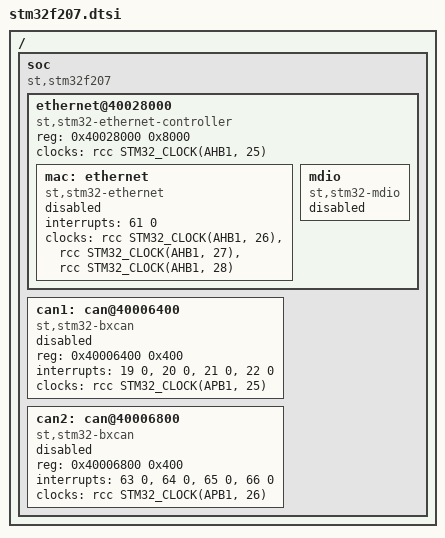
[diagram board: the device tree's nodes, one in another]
/*
 * Copyright (c) 2018 qianfan Zhao
 *
 * SPDX-License-Identifier: Apache-2.0
 */

#include <st/f2/stm32f2.dtsi>

/ {
	soc {
		compatible = "st,stm32f207", "st,stm32f2", "simple-bus";

		ethernet@40028000 {
			reg = <0x40028000 0x8000>;
			compatible = "st,stm32-ethernet-controller";
			clock-names = "stm-eth";
			clocks = <&rcc STM32_CLOCK(AHB1, 25)>;

			mac: ethernet {
				compatible = "st,stm32-ethernet";
				interrupts = <61 0>;
				clock-names = "mac-clk-tx", "mac-clk-rx",
					      "mac-clk-ptp";
				clocks = <&rcc STM32_CLOCK(AHB1, 26)>,
					 <&rcc STM32_CLOCK(AHB1, 27)>,
					 <&rcc STM32_CLOCK(AHB1, 28)>;
				status = "disabled";
			};

			mdio: mdio {
				compatible = "st,stm32-mdio";
				#address-cells = <1>;
				#size-cells = <0>;
				status = "disabled";
			};
		};

		can1: can@40006400 {
			compatible = "st,stm32-bxcan";
			reg = <0x40006400 0x400>;
			interrupts = <19 0>, <20 0>, <21 0>, <22 0>;
			interrupt-names = "TX", "RX0", "RX1", "SCE";
			clocks = <&rcc STM32_CLOCK(APB1, 25)>;
			status = "disabled";
		};

		can2: can@40006800 {
			compatible = "st,stm32-bxcan";
			reg = <0x40006800 0x400>;
			interrupts = <63 0>, <64 0>, <65 0>, <66 0>;
			interrupt-names = "TX", "RX0", "RX1", "SCE";
			clocks = <&rcc STM32_CLOCK(APB1, 26)>;
			status = "disabled";
		};
	};
};
